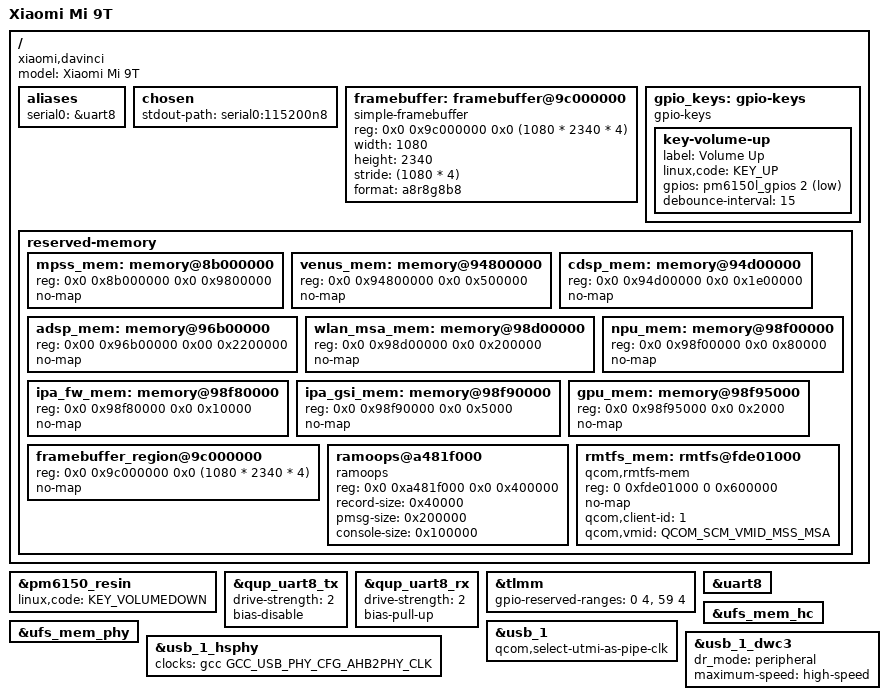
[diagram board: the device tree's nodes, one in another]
// SPDX-License-Identifier: BSD-3-Clause
/dts-v1/;

#include <dt-bindings/arm/qcom,ids.h>
#include <dt-bindings/firmware/qcom,scm.h>
#include <dt-bindings/gpio/gpio.h>
#include <dt-bindings/input/linux-event-codes.h>

#include "sm7150.dtsi"
#include "pm6150.dtsi"
#include "pm6150l.dtsi"

/delete-node/ &mpss_mem;
/delete-node/ &venus_mem;
/delete-node/ &cdsp_mem;
/delete-node/ &adsp_mem;
/delete-node/ &wlan_msa_mem;
/delete-node/ &npu_mem;
/delete-node/ &ipa_fw_mem;
/delete-node/ &ipa_gsi_mem;
/delete-node/ &gpu_mem;

/ {
	/*
	 * Xiaomi Mi 9T
	 * Xiaomi Redmi K20
	 */
	model = "Xiaomi Mi 9T";
	compatible = "xiaomi,davinci", "qcom,sm7150";

	aliases {
		serial0 = &uart8;
	};

	chosen {
		stdout-path = "serial0:115200n8";
	};

	framebuffer: framebuffer@9c000000 {
		compatible = "simple-framebuffer";
		reg = <0x0 0x9c000000 0x0 (1080 * 2340 * 4)>;
		width = <1080>;
		height = <2340>;
		stride = <(1080 * 4)>;
		format = "a8r8g8b8";
	};

	gpio_keys: gpio-keys {
		compatible = "gpio-keys";

		key-volume-up {
			label = "Volume Up";
			linux,code = <KEY_UP>; /* KEY_VOLUMEUP */
			gpios = <&pm6150l_gpios 2 GPIO_ACTIVE_LOW>;
			debounce-interval = <15>;
		};
	};

	reserved-memory {
		mpss_mem: memory@8b000000 {
			reg = <0x0 0x8b000000 0x0 0x9800000>;
			no-map;
		};

		venus_mem: memory@94800000 {
			reg = <0x0 0x94800000 0x0 0x500000>;
			no-map;
		};

		cdsp_mem: memory@94d00000 {
			reg = <0x0 0x94d00000 0x0 0x1e00000>;
			no-map;
		};

		adsp_mem: memory@96b00000 {
			reg = <0x00 0x96b00000 0x00 0x2200000>;
			no-map;
		};

		wlan_msa_mem: memory@98d00000 {
			reg = <0x0 0x98d00000 0x0 0x200000>;
			no-map;
		};

		npu_mem: memory@98f00000 {
			reg = <0x0 0x98f00000 0x0 0x80000>;
			no-map;
		};

		ipa_fw_mem: memory@98f80000 {
			reg = <0x0 0x98f80000 0x0 0x10000>;
			no-map;
		};

		ipa_gsi_mem: memory@98f90000 {
			reg = <0x0 0x98f90000 0x0 0x5000>;
			no-map;
		};

		gpu_mem: memory@98f95000 {
			reg = <0x0 0x98f95000 0x0 0x2000>;
			no-map;
		};

		framebuffer_region@9c000000 {
			reg = <0x0 0x9c000000 0x0 (1080 * 2340 * 4)>;
			no-map;
		};

		ramoops@a481f000 {
			compatible = "ramoops";
			reg = <0x0 0xa481f000 0x0 0x400000>;

			record-size = <0x40000>;
			pmsg-size = <0x200000>;
			console-size = <0x100000>;
		};

		rmtfs_mem: rmtfs@fde01000 {
			compatible = "qcom,rmtfs-mem";
			reg = <0 0xfde01000 0 0x600000>;
			no-map;

			qcom,client-id = <1>;
			qcom,vmid = <QCOM_SCM_VMID_MSS_MSA>;
		};
	};
};

&pm6150_resin {
	linux,code = <KEY_VOLUMEDOWN>;
	status = "okay";
};

&qup_uart8_tx {
	drive-strength = <2>;
	bias-disable;
};

&qup_uart8_rx {
	drive-strength = <2>;
	bias-pull-up;
};

&tlmm {
	/* Reserved I/Os for NFC and FP */
	gpio-reserved-ranges = <0 4>, <59 4>;
};

&uart8 {
	status = "okay";
};

&ufs_mem_hc {
	status = "okay";
};

&ufs_mem_phy {
	status = "okay";
};

&usb_1 {
	qcom,select-utmi-as-pipe-clk;
	status = "okay";
};

&usb_1_dwc3 {
	dr_mode = "peripheral";
	maximum-speed = "high-speed";
};

&usb_1_hsphy {
	/* Remove ref clk because rmphcc isn't available */
	clocks = <&gcc GCC_USB_PHY_CFG_AHB2PHY_CLK>;
	clock-names = "cfg_ahb";

	status = "okay";
};
